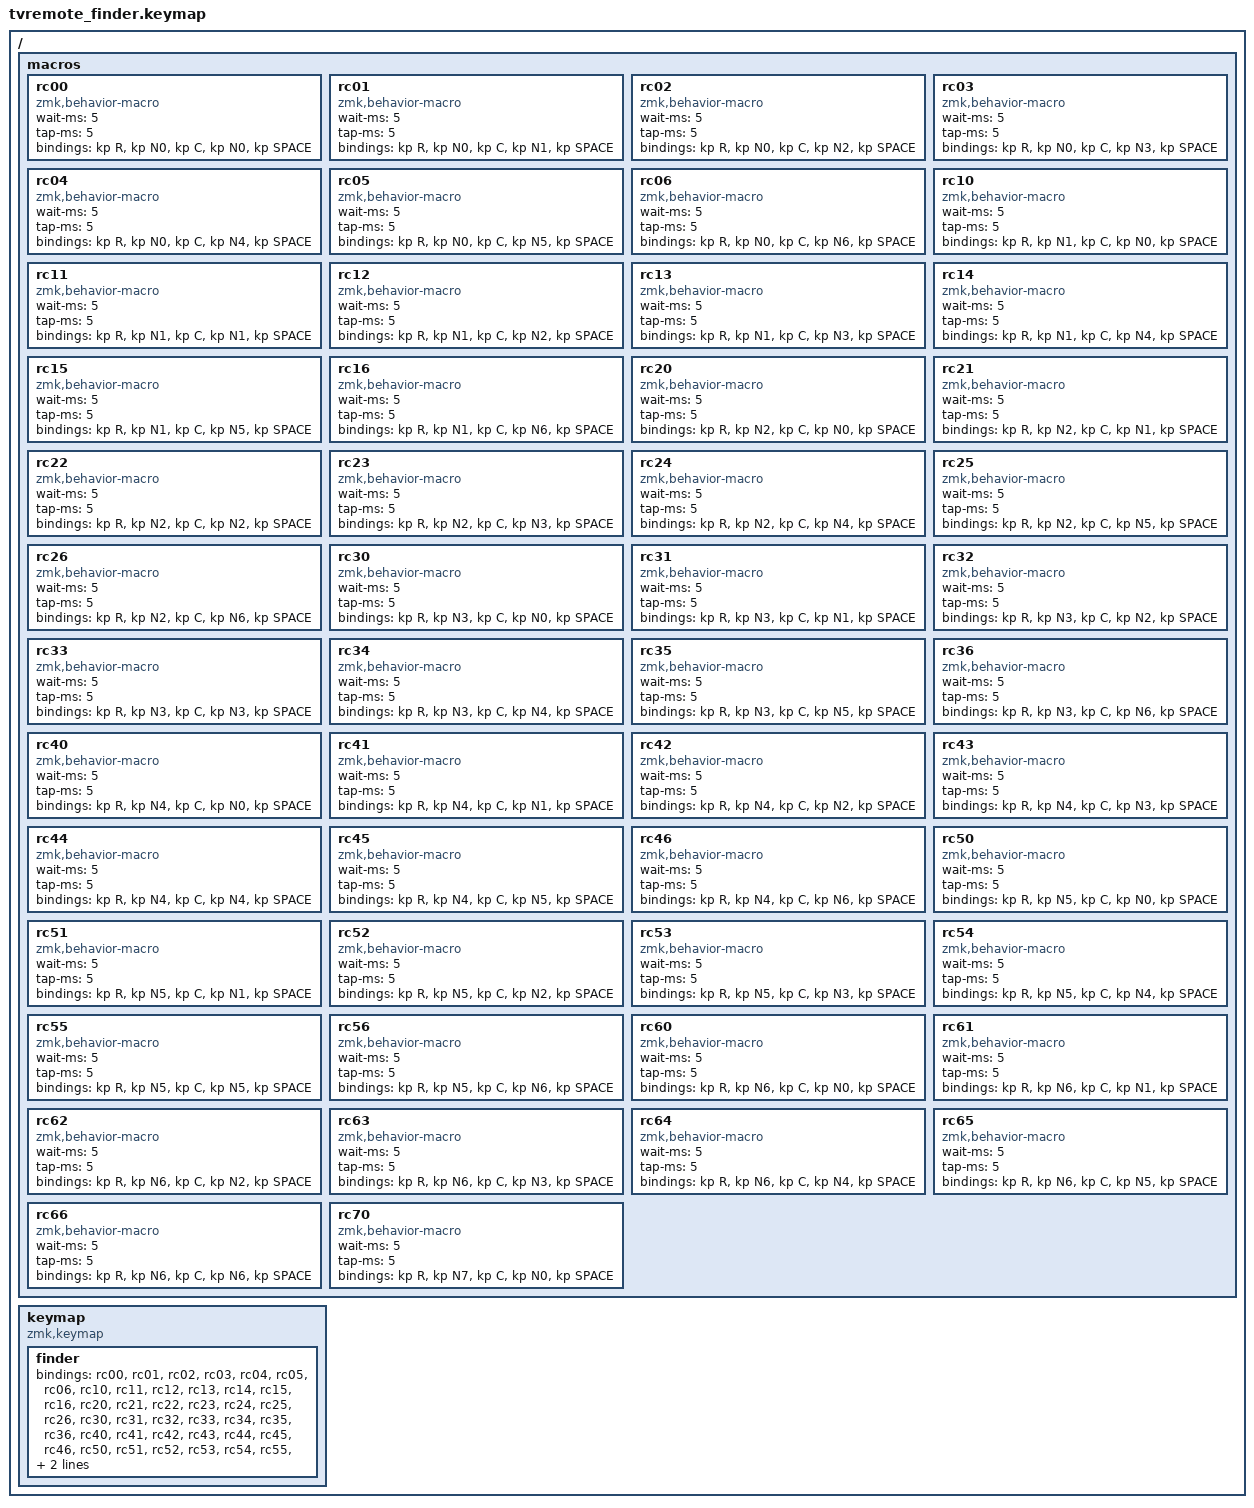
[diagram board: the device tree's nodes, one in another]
/*
 * Matrix check for the replacement PCB: each button types its row and column
 * ("r3c5 "). Plug in over USB, open Notepad and press every button; compare
 * with the key names in the comments (from bt-remote/pcb/matrix.json).
 *
 * Generated by bt-remote/pcb/make_zmk.py.
 */

#include <behaviors.dtsi>
#include <dt-bindings/zmk/keys.h>

/ {
    macros {
        rc00: rc00 {
            compatible = "zmk,behavior-macro";
            #binding-cells = <0>;
            wait-ms = <5>;
            tap-ms = <5>;
            bindings = <&kp R &kp N0 &kp C &kp N0 &kp SPACE>;
        };
        rc01: rc01 {
            compatible = "zmk,behavior-macro";
            #binding-cells = <0>;
            wait-ms = <5>;
            tap-ms = <5>;
            bindings = <&kp R &kp N0 &kp C &kp N1 &kp SPACE>;
        };
        rc02: rc02 {
            compatible = "zmk,behavior-macro";
            #binding-cells = <0>;
            wait-ms = <5>;
            tap-ms = <5>;
            bindings = <&kp R &kp N0 &kp C &kp N2 &kp SPACE>;
        };
        rc03: rc03 {
            compatible = "zmk,behavior-macro";
            #binding-cells = <0>;
            wait-ms = <5>;
            tap-ms = <5>;
            bindings = <&kp R &kp N0 &kp C &kp N3 &kp SPACE>;
        };
        rc04: rc04 {
            compatible = "zmk,behavior-macro";
            #binding-cells = <0>;
            wait-ms = <5>;
            tap-ms = <5>;
            bindings = <&kp R &kp N0 &kp C &kp N4 &kp SPACE>;
        };
        rc05: rc05 {
            compatible = "zmk,behavior-macro";
            #binding-cells = <0>;
            wait-ms = <5>;
            tap-ms = <5>;
            bindings = <&kp R &kp N0 &kp C &kp N5 &kp SPACE>;
        };
        rc06: rc06 {
            compatible = "zmk,behavior-macro";
            #binding-cells = <0>;
            wait-ms = <5>;
            tap-ms = <5>;
            bindings = <&kp R &kp N0 &kp C &kp N6 &kp SPACE>;
        };
        rc10: rc10 {
            compatible = "zmk,behavior-macro";
            #binding-cells = <0>;
            wait-ms = <5>;
            tap-ms = <5>;
            bindings = <&kp R &kp N1 &kp C &kp N0 &kp SPACE>;
        };
        rc11: rc11 {
            compatible = "zmk,behavior-macro";
            #binding-cells = <0>;
            wait-ms = <5>;
            tap-ms = <5>;
            bindings = <&kp R &kp N1 &kp C &kp N1 &kp SPACE>;
        };
        rc12: rc12 {
            compatible = "zmk,behavior-macro";
            #binding-cells = <0>;
            wait-ms = <5>;
            tap-ms = <5>;
            bindings = <&kp R &kp N1 &kp C &kp N2 &kp SPACE>;
        };
        rc13: rc13 {
            compatible = "zmk,behavior-macro";
            #binding-cells = <0>;
            wait-ms = <5>;
            tap-ms = <5>;
            bindings = <&kp R &kp N1 &kp C &kp N3 &kp SPACE>;
        };
        rc14: rc14 {
            compatible = "zmk,behavior-macro";
            #binding-cells = <0>;
            wait-ms = <5>;
            tap-ms = <5>;
            bindings = <&kp R &kp N1 &kp C &kp N4 &kp SPACE>;
        };
        rc15: rc15 {
            compatible = "zmk,behavior-macro";
            #binding-cells = <0>;
            wait-ms = <5>;
            tap-ms = <5>;
            bindings = <&kp R &kp N1 &kp C &kp N5 &kp SPACE>;
        };
        rc16: rc16 {
            compatible = "zmk,behavior-macro";
            #binding-cells = <0>;
            wait-ms = <5>;
            tap-ms = <5>;
            bindings = <&kp R &kp N1 &kp C &kp N6 &kp SPACE>;
        };
        rc20: rc20 {
            compatible = "zmk,behavior-macro";
            #binding-cells = <0>;
            wait-ms = <5>;
            tap-ms = <5>;
            bindings = <&kp R &kp N2 &kp C &kp N0 &kp SPACE>;
        };
        rc21: rc21 {
            compatible = "zmk,behavior-macro";
            #binding-cells = <0>;
            wait-ms = <5>;
            tap-ms = <5>;
            bindings = <&kp R &kp N2 &kp C &kp N1 &kp SPACE>;
        };
        rc22: rc22 {
            compatible = "zmk,behavior-macro";
            #binding-cells = <0>;
            wait-ms = <5>;
            tap-ms = <5>;
            bindings = <&kp R &kp N2 &kp C &kp N2 &kp SPACE>;
        };
        rc23: rc23 {
            compatible = "zmk,behavior-macro";
            #binding-cells = <0>;
            wait-ms = <5>;
            tap-ms = <5>;
            bindings = <&kp R &kp N2 &kp C &kp N3 &kp SPACE>;
        };
        rc24: rc24 {
            compatible = "zmk,behavior-macro";
            #binding-cells = <0>;
            wait-ms = <5>;
            tap-ms = <5>;
            bindings = <&kp R &kp N2 &kp C &kp N4 &kp SPACE>;
        };
        rc25: rc25 {
            compatible = "zmk,behavior-macro";
            #binding-cells = <0>;
            wait-ms = <5>;
            tap-ms = <5>;
            bindings = <&kp R &kp N2 &kp C &kp N5 &kp SPACE>;
        };
        rc26: rc26 {
            compatible = "zmk,behavior-macro";
            #binding-cells = <0>;
            wait-ms = <5>;
            tap-ms = <5>;
            bindings = <&kp R &kp N2 &kp C &kp N6 &kp SPACE>;
        };
        rc30: rc30 {
            compatible = "zmk,behavior-macro";
            #binding-cells = <0>;
            wait-ms = <5>;
            tap-ms = <5>;
            bindings = <&kp R &kp N3 &kp C &kp N0 &kp SPACE>;
        };
        rc31: rc31 {
            compatible = "zmk,behavior-macro";
            #binding-cells = <0>;
            wait-ms = <5>;
            tap-ms = <5>;
            bindings = <&kp R &kp N3 &kp C &kp N1 &kp SPACE>;
        };
        rc32: rc32 {
            compatible = "zmk,behavior-macro";
            #binding-cells = <0>;
            wait-ms = <5>;
            tap-ms = <5>;
            bindings = <&kp R &kp N3 &kp C &kp N2 &kp SPACE>;
        };
        rc33: rc33 {
            compatible = "zmk,behavior-macro";
            #binding-cells = <0>;
            wait-ms = <5>;
            tap-ms = <5>;
            bindings = <&kp R &kp N3 &kp C &kp N3 &kp SPACE>;
        };
        rc34: rc34 {
            compatible = "zmk,behavior-macro";
            #binding-cells = <0>;
            wait-ms = <5>;
            tap-ms = <5>;
            bindings = <&kp R &kp N3 &kp C &kp N4 &kp SPACE>;
        };
        rc35: rc35 {
            compatible = "zmk,behavior-macro";
            #binding-cells = <0>;
            wait-ms = <5>;
            tap-ms = <5>;
            bindings = <&kp R &kp N3 &kp C &kp N5 &kp SPACE>;
        };
        rc36: rc36 {
            compatible = "zmk,behavior-macro";
            #binding-cells = <0>;
            wait-ms = <5>;
            tap-ms = <5>;
            bindings = <&kp R &kp N3 &kp C &kp N6 &kp SPACE>;
        };
        rc40: rc40 {
            compatible = "zmk,behavior-macro";
            #binding-cells = <0>;
            wait-ms = <5>;
            tap-ms = <5>;
            bindings = <&kp R &kp N4 &kp C &kp N0 &kp SPACE>;
        };
        rc41: rc41 {
            compatible = "zmk,behavior-macro";
            #binding-cells = <0>;
            wait-ms = <5>;
            tap-ms = <5>;
            bindings = <&kp R &kp N4 &kp C &kp N1 &kp SPACE>;
        };
        rc42: rc42 {
            compatible = "zmk,behavior-macro";
            #binding-cells = <0>;
            wait-ms = <5>;
            tap-ms = <5>;
            bindings = <&kp R &kp N4 &kp C &kp N2 &kp SPACE>;
        };
        rc43: rc43 {
            compatible = "zmk,behavior-macro";
            #binding-cells = <0>;
            wait-ms = <5>;
            tap-ms = <5>;
            bindings = <&kp R &kp N4 &kp C &kp N3 &kp SPACE>;
        };
        rc44: rc44 {
            compatible = "zmk,behavior-macro";
            #binding-cells = <0>;
            wait-ms = <5>;
            tap-ms = <5>;
            bindings = <&kp R &kp N4 &kp C &kp N4 &kp SPACE>;
        };
        rc45: rc45 {
            compatible = "zmk,behavior-macro";
            #binding-cells = <0>;
            wait-ms = <5>;
            tap-ms = <5>;
            bindings = <&kp R &kp N4 &kp C &kp N5 &kp SPACE>;
        };
        rc46: rc46 {
            compatible = "zmk,behavior-macro";
            #binding-cells = <0>;
            wait-ms = <5>;
            tap-ms = <5>;
            bindings = <&kp R &kp N4 &kp C &kp N6 &kp SPACE>;
        };
        rc50: rc50 {
            compatible = "zmk,behavior-macro";
            #binding-cells = <0>;
            wait-ms = <5>;
            tap-ms = <5>;
            bindings = <&kp R &kp N5 &kp C &kp N0 &kp SPACE>;
        };
        rc51: rc51 {
            compatible = "zmk,behavior-macro";
            #binding-cells = <0>;
            wait-ms = <5>;
            tap-ms = <5>;
            bindings = <&kp R &kp N5 &kp C &kp N1 &kp SPACE>;
        };
        rc52: rc52 {
            compatible = "zmk,behavior-macro";
            #binding-cells = <0>;
            wait-ms = <5>;
            tap-ms = <5>;
            bindings = <&kp R &kp N5 &kp C &kp N2 &kp SPACE>;
        };
        rc53: rc53 {
            compatible = "zmk,behavior-macro";
            #binding-cells = <0>;
            wait-ms = <5>;
            tap-ms = <5>;
            bindings = <&kp R &kp N5 &kp C &kp N3 &kp SPACE>;
        };
        rc54: rc54 {
            compatible = "zmk,behavior-macro";
            #binding-cells = <0>;
            wait-ms = <5>;
            tap-ms = <5>;
            bindings = <&kp R &kp N5 &kp C &kp N4 &kp SPACE>;
        };
        rc55: rc55 {
            compatible = "zmk,behavior-macro";
            #binding-cells = <0>;
            wait-ms = <5>;
            tap-ms = <5>;
            bindings = <&kp R &kp N5 &kp C &kp N5 &kp SPACE>;
        };
        rc56: rc56 {
            compatible = "zmk,behavior-macro";
            #binding-cells = <0>;
            wait-ms = <5>;
            tap-ms = <5>;
            bindings = <&kp R &kp N5 &kp C &kp N6 &kp SPACE>;
        };
        rc60: rc60 {
            compatible = "zmk,behavior-macro";
            #binding-cells = <0>;
            wait-ms = <5>;
            tap-ms = <5>;
            bindings = <&kp R &kp N6 &kp C &kp N0 &kp SPACE>;
        };
        rc61: rc61 {
            compatible = "zmk,behavior-macro";
            #binding-cells = <0>;
            wait-ms = <5>;
            tap-ms = <5>;
            bindings = <&kp R &kp N6 &kp C &kp N1 &kp SPACE>;
        };
        rc62: rc62 {
            compatible = "zmk,behavior-macro";
            #binding-cells = <0>;
            wait-ms = <5>;
            tap-ms = <5>;
            bindings = <&kp R &kp N6 &kp C &kp N2 &kp SPACE>;
        };
        rc63: rc63 {
            compatible = "zmk,behavior-macro";
            #binding-cells = <0>;
            wait-ms = <5>;
            tap-ms = <5>;
            bindings = <&kp R &kp N6 &kp C &kp N3 &kp SPACE>;
        };
        rc64: rc64 {
            compatible = "zmk,behavior-macro";
            #binding-cells = <0>;
            wait-ms = <5>;
            tap-ms = <5>;
            bindings = <&kp R &kp N6 &kp C &kp N4 &kp SPACE>;
        };
        rc65: rc65 {
            compatible = "zmk,behavior-macro";
            #binding-cells = <0>;
            wait-ms = <5>;
            tap-ms = <5>;
            bindings = <&kp R &kp N6 &kp C &kp N5 &kp SPACE>;
        };
        rc66: rc66 {
            compatible = "zmk,behavior-macro";
            #binding-cells = <0>;
            wait-ms = <5>;
            tap-ms = <5>;
            bindings = <&kp R &kp N6 &kp C &kp N6 &kp SPACE>;
        };
        rc70: rc70 {
            compatible = "zmk,behavior-macro";
            #binding-cells = <0>;
            wait-ms = <5>;
            tap-ms = <5>;
            bindings = <&kp R &kp N7 &kp C &kp N0 &kp SPACE>;
        };
    };

    keymap {
        compatible = "zmk,keymap";

        finder {
            bindings = <
                // row 0
                &rc00    // 1
                &rc01    // DVD
                &rc02    // EJECT
                &rc03    // VIDEO
                &rc04    // VCR PLUS
                &rc05    // POWER
                &rc06    // CH+

                // row 1
                &rc10    // 4
                &rc11    // 5
                &rc12    // 2
                &rc13    // 6
                &rc14    // 3
                &rc15    // VOL+
                &rc16    // CH-

                // row 2
                &rc20    // CLEAR
                &rc21    // 7
                &rc22    // 0
                &rc23    // 8
                &rc24    // ENTER
                &rc25    // 9
                &rc26    // VOL-

                // row 3
                &rc30    // AUDIO
                &rc31    // SET UP
                &rc32    // SUBTITLE
                &rc33    // ANGLE
                &rc34    // REPEAT
                &rc35    // TV/VIDEO
                &rc36    // ZOOM

                // row 4
                &rc40    // REC
                &rc41    // REPEAT2
                &rc42    // SKIP
                &rc43    // SCAN REW
                &rc44    // SURROUND
                &rc45    // SCAN F.F
                &rc46    // INPUT

                // row 5
                &rc50    // PLAY
                &rc51    // SP/EP
                &rc52    // UP
                &rc53    // PAUSE
                &rc54    // PREV
                &rc55    // STOP
                &rc56    // NEXT

                // row 6
                &rc60    // DISPLAY
                &rc61    // LEFT
                &rc62    // TOP MENU
                &rc63    // DOWN
                &rc64    // SELECT
                &rc65    // RIGHT
                &rc66    // RETURN

                // row 7
                &rc70    // MENU
            >;
        };
    };
};
